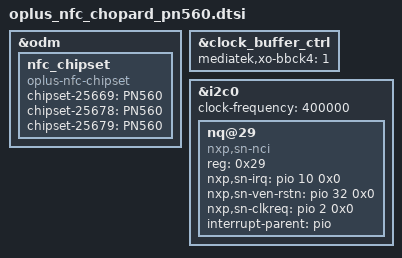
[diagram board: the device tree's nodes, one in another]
/**********************************************************************************
* Copyright (c)  2008-2020  Guangdong oplus Mobile Comm Corp., Ltd
*
***********************************************************************************/
&odm {
     nfc_chipset:nfc_chipset {
        compatible = "oplus-nfc-chipset";
        chipset-25669 = "PN560";
        chipset-25678 = "PN560";
        chipset-25679 = "PN560";
//        manifest = "/odm/etc/vintf/manifest_nfc_pn560.xml";
     };
};

&clock_buffer_ctrl {
	mediatek,xo-bbck4 = <1>;
};

&i2c0 {
       status = "okay";
       clock-frequency = <400000>;
       nq@29 {
               compatible = "nxp,sn-nci";
               reg = <0x29>;
               nxp,sn-irq = <&pio 10 0x0>;
               nxp,sn-ven-rstn = <&pio 32 0x0>;
               nxp,sn-clkreq = <&pio 2 0x0>;
               interrupt-parent = <&pio>;
       };
};

